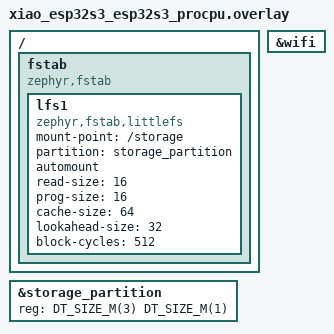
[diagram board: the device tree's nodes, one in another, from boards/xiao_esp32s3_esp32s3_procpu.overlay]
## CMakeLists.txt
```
# Copyright (c) 2022-2023 Golioth, Inc.
# SPDX-License-Identifier: Apache-2.0

cmake_minimum_required(VERSION 3.20.0)

# Conditionally add NCS/Zephyr-specific config
set(NCS_BOARD_LIST "nrf9160dk_nrf9160_ns")

if (BOARD IN_LIST NCS_BOARD_LIST)
    list(APPEND EXTRA_CONF_FILE prj-ncs.conf)
else()
    list(APPEND EXTRA_CONF_FILE prj-zephyr.conf)
endif(BOARD IN_LIST NCS_BOARD_LIST)

find_package(Zephyr REQUIRED HINTS $ENV{ZEPHYR_BASE})

project(example_template)

target_sources(app PRIVATE src/main.c)
target_sources_ifdef(CONFIG_BOOTLOADER_MCUBOOT app PRIVATE src/flash.c)
if(CONFIG_SOC_FAMILY_ESPRESSIF_ESP32 AND NOT CONFIG_BOOTLOADER_MCUBOOT)
    target_sources_ifndef(CONFIG_BOOTLOADER_MCUBOOT app PRIVATE src/mcuboot_assert.c)
endif()
```

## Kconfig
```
# Copyright (c) 2022-2023 Golioth, Inc.
# SPDX-License-Identifier: Apache-2.0

mainmenu "Golioth application options"

if DNS_RESOLVER

config DNS_SERVER_IP_ADDRESSES
	default y

config DNS_SERVER1
	default "1.1.1.1"

endif # DNS_RESOLVER

configdefault MCUBOOT_SHELL
	bool
    default y

# Workaround for not being able to have commas in macro arguments
DT_CHOSEN_ZEPHYR_DISPLAY := zephyr,display

configdefault LVGL
	bool
    default y if $(dt_chosen_enabled,$(DT_CHOSEN_ZEPHYR_DISPLAY))

configdefault LV_MEM_CUSTOM
	bool
    default y

configdefault LV_USE_LOG
	bool
    default y

configdefault LV_USE_LABEL
	bool
    default y

configdefault LV_USE_BTN
	bool
    default y

configdefault LV_USE_ARC
	bool
    default y

configdefault LV_USE_IMG
	bool
    default y

configdefault LV_USE_MONKEY
	bool
    default y

configdefault LV_FONT_MONTSERRAT_14
	bool
    default y

configdefault LV_Z_SHELL
	bool
    default y

configdefault LV_Z_MEM_POOL_SIZE
	int
    default 16384

source "Kconfig.zephyr"
```

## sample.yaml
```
# Copyright (c) 2024 Golioth, Inc.
# SPDX-License-Identifier: Apache-2.0

sample:
  description: Golioth Example Download Photo
  name: example_download_photo
common:
  harness: net
  platform_allow: >
    nrf9160dk_nrf9160_ns
  tags: golioth
```

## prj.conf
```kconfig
# Copyright (c) 2024 Golioth, Inc.
# SPDX-License-Identifier: Apache-2.0

# Enable Golioth Firmware SDK
CONFIG_GOLIOTH_FIRMWARE_SDK=y

# Golioth services used in this app
CONFIG_GOLIOTH_FW_UPDATE=y
CONFIG_GOLIOTH_SETTINGS=y
CONFIG_LOG_BACKEND_GOLIOTH=y

# Enable common sample library
CONFIG_GOLIOTH_SAMPLE_COMMON=y

# Configure Golioth SDK dependencies
CONFIG_ZVFS_EVENTFD_MAX=14
CONFIG_LOG_PROCESS_THREAD_STACK_SIZE=1536
CONFIG_MBEDTLS_ENABLE_HEAP=y
CONFIG_MBEDTLS_HEAP_SIZE=10240

CONFIG_NETWORKING=y
CONFIG_NET_IPV4=y
CONFIG_ZVFS_OPEN_MAX=23

# Application
CONFIG_MAIN_STACK_SIZE=8192
CONFIG_SYSTEM_WORKQUEUE_STACK_SIZE=2048
CONFIG_NET_LOG=y
CONFIG_NET_SHELL=y
CONFIG_REBOOT=y

# Flash memory (etc.) for firmware upgrade
CONFIG_FLASH=y
CONFIG_FLASH_MAP=y
CONFIG_STREAM_FLASH=y
CONFIG_IMG_MANAGER=y
CONFIG_IMG_ERASE_PROGRESSIVELY=y
CONFIG_REBOOT=y

# The rest of the runtime credentials config
CONFIG_SETTINGS=y
CONFIG_SETTINGS_RUNTIME=y
CONFIG_GOLIOTH_SAMPLE_SETTINGS=y
CONFIG_GOLIOTH_SAMPLE_SETTINGS_AUTOLOAD=y
CONFIG_GOLIOTH_SAMPLE_SETTINGS_SHELL=y

# Multiple OTA components to e.g. handle firmware upgrade and photo in single
# release
CONFIG_GOLIOTH_OTA_MAX_NUM_COMPONENTS=2

CONFIG_FILE_SYSTEM=y
CONFIG_FILE_SYSTEM_LITTLEFS=y

CONFIG_DISPLAY=y
CONFIG_DISPLAY_LOG_LEVEL_ERR=y

CONFIG_LOG=y
CONFIG_SHELL=y

CONFIG_COMMON_LIBC_MALLOC_ARENA_SIZE=65536
```

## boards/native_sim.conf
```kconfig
# Use offloaded sockets using host BSD sockets
CONFIG_ETH_DRIVER=n
CONFIG_ETH_NATIVE_POSIX=n
CONFIG_NET_DRIVERS=y
CONFIG_NET_SOCKETS=y
CONFIG_NET_SOCKETS_OFFLOAD=y
CONFIG_NET_NATIVE_OFFLOADED_SOCKETS=y
CONFIG_HEAP_MEM_POOL_SIZE=1024

# Use embedded libc to use Zephyr's eventfd instead of host eventfd
CONFIG_PICOLIBC=y

# Static networking
CONFIG_NET_CONFIG_LOG_LEVEL_DBG=y
CONFIG_NET_CONFIG_SETTINGS=y
CONFIG_NET_CONFIG_NEED_IPV4=y
CONFIG_NET_CONFIG_MY_IPV4_ADDR="192.0.2.1"
CONFIG_NET_CONFIG_MY_IPV4_GW="192.0.2.2"
CONFIG_NET_CONFIG_PEER_IPV4_ADDR="192.0.2.2"

# Disabled shell for using standard output
CONFIG_NET_SHELL=n
CONFIG_SHELL=n

# Make it the same as xiao_esp32s3 to use the same compiled images
CONFIG_LV_COLOR_16_SWAP=y
```

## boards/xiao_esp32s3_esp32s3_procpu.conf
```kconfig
CONFIG_WIFI=y
CONFIG_COMMON_LIBC_MALLOC_ARENA_SIZE=32768

CONFIG_NET_L2_ETHERNET=y

CONFIG_NET_DHCPV4=y

CONFIG_ESP32_WIFI_STA_AUTO_DHCPV4=y

CONFIG_NET_L2_WIFI_SHELL=y
CONFIG_GOLIOTH_SAMPLE_WIFI=y

# Runtime credentials for WiFi
CONFIG_GOLIOTH_SAMPLE_WIFI_SETTINGS=y

CONFIG_ESPTOOLPY_FLASHSIZE_8MB=y
```

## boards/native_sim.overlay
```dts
/ {
	fstab {
		compatible = "zephyr,fstab";
		lfs1: lfs1 {
			compatible = "zephyr,fstab,littlefs";
			mount-point = "/storage";
			partition = <&storage_partition>;
			automount;
			read-size = <16>;
			prog-size = <16>;
			cache-size = <64>;
			lookahead-size = <32>;
			block-cycles = <512>;
		};
	};
};

&storage_partition {
	reg = <DT_SIZE_M(1) DT_SIZE_M(1)>;
};
```

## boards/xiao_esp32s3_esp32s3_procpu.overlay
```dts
/ {
	fstab {
		compatible = "zephyr,fstab";
		lfs1: lfs1 {
			compatible = "zephyr,fstab,littlefs";
			mount-point = "/storage";
			partition = <&storage_partition>;
			automount;
			read-size = <16>;
			prog-size = <16>;
			cache-size = <64>;
			lookahead-size = <32>;
			block-cycles = <512>;
		};
	};
};

&storage_partition {
	reg = <DT_SIZE_M(3) DT_SIZE_M(1)>;
};

&wifi {
	status = "okay";
};
```

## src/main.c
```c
/*
 * Copyright (c) 2022-2023 Golioth, Inc.
 *
 * SPDX-License-Identifier: Apache-2.0
 */

#include <zephyr/logging/log.h>
LOG_MODULE_REGISTER(example_download_photo, LOG_LEVEL_DBG);

#include <app_version.h>
#include <golioth/client.h>
#include <golioth/ota.h>
#include <golioth/settings.h>
#include <samples/common/net_connect.h>
#include <samples/common/sample_credentials.h>
#include <zephyr/kernel.h>
#include <zephyr/fs/fs.h>

#include <zephyr/drivers/display.h>
#include <lvgl.h>

#include <mbedtls/sha256.h>

/* Current firmware version; update in VERSION file */
static const char *_current_version =
    STRINGIFY(APP_VERSION_MAJOR) "." STRINGIFY(APP_VERSION_MINOR) "." STRINGIFY(APP_PATCHLEVEL);

static struct golioth_client *client;
K_SEM_DEFINE(connected, 0, 1);

static k_tid_t _system_thread = 0;

static int32_t _loop_delay_s = 10;
#define LOOP_DELAY_S_MAX 43200
#define LOOP_DELAY_S_MIN 0


static void wake_system_thread(void)
{
    k_wakeup(_system_thread);
}

static void on_client_event(struct golioth_client *client,
                            enum golioth_client_event event,
                            void *arg)
{
    bool is_connected = (event == GOLIOTH_CLIENT_EVENT_CONNECTED);

    if (is_connected)
    {
        k_sem_give(&connected);
    }
    LOG_INF("Golioth client %s", is_connected ? "connected" : "disconnected");
}

static enum golioth_settings_status on_loop_delay_setting(int32_t new_value, void *arg)
{
    _loop_delay_s = new_value;
    LOG_INF("Set loop delay to %i seconds", new_value);
    wake_system_thread();
    return GOLIOTH_SETTINGS_SUCCESS;
}

static int app_settings_register(struct golioth_client *client)
{
    struct golioth_settings *settings = golioth_settings_init(client);

    int err = golioth_settings_register_int_with_range(settings,
                                                       "LOOP_DELAY_S",
                                                       LOOP_DELAY_S_MIN,
                                                       LOOP_DELAY_S_MAX,
                                                       on_loop_delay_setting,
                                                       NULL);

    if (err)
    {
        LOG_ERR("Failed to register settings callback: %d", err);
    }

    return err;
}

struct ota_observe_data
{
    struct golioth_ota_manifest manifest;
    struct k_sem manifest_received;
};

static void on_ota_manifest(struct golioth_client *client,
                            const struct golioth_response *response,
                            const char *path,
                            const uint8_t *payload,
                            size_t payload_size,
                            void *arg)
{
    struct ota_observe_data *data = arg;

    LOG_INF("Manifest received");

    if (response->status != GOLIOTH_OK)
    {
        return;
    }

    LOG_HEXDUMP_INF(payload, payload_size, "Received OTA manifest");

    enum golioth_ota_state state = golioth_ota_get_state();
    if (state == GOLIOTH_OTA_STATE_DOWNLOADING)
    {
        GLTH_LOGW(TAG, "Ignoring manifest while download in progress");
        return;
    }

    enum golioth_status status =
        golioth_ota_payload_as_manifest(payload, payload_size, &data->manifest);
    if (status != GOLIOTH_OK)
    {
        GLTH_LOGE(TAG, "Failed to parse manifest: %s", golioth_status_to_str(status));
        return;
    }

    if (data->manifest.num_components > 0) {
        k_sem_give(&data->manifest_received);
    }
}

enum golioth_status write_block(const struct golioth_ota_component *component,
                                uint32_t block_idx,
                                uint8_t *block_buffer,
                                size_t block_size,
                                bool is_last,
                                void *arg)
{
    const char *filename = component->package;
    struct fs_file_t fp = {};
    fs_mode_t flags = FS_O_CREATE | FS_O_WRITE;
    char path[32];
    int err;
    ssize_t ret;

    if (block_idx == 0) {
        flags |= FS_O_TRUNC;
    }

    sprintf(path, "/storage/%s", filename);

    err = fs_open(&fp, path, flags);
    if (err) {
        LOG_ERR("Failed to open %s: %d", filename, err);

        return err;
    }

    err = fs_seek(&fp, block_idx * CONFIG_GOLIOTH_BLOCKWISE_DOWNLOAD_BUFFER_SIZE, FS_SEEK_SET);
    if (err) {
        goto fp_close;
    }

    ret = fs_write(&fp, block_buffer, block_size);
    if (ret < 0) {
        goto fp_close;
    }

fp_close:
    fs_close(&fp);

    return GOLIOTH_OK;
}

static int greeting_show(void)
{
    mbedtls_sha256_context ctx;
    char hash[32];
    struct fs_file_t greeting_fp = {};
    int err;
    ssize_t ret;

    mbedtls_sha256_init(&ctx);

    err = mbedtls_sha256_starts(&ctx, 0);
    if (err) {
        return -EFAULT;
    }

    err = fs_open(&greeting_fp, "/storage/greeting", FS_O_READ);
    if (err) {
        LOG_ERR("Failed to open greeting: %d", err);

        return err;
    }

    while (true) {
        uint8_t buffer[16];

        ret = fs_read(&greeting_fp, buffer, sizeof(buffer));
        if (ret < 0) {
            err = ret;
            LOG_ERR("Failed to read: %d", err);
            goto greeting_close;
        }
        if (ret == 0) {
            break;
        }

        LOG_HEXDUMP_INF(buffer, ret, "greeting");

        err = mbedtls_sha256_update(&ctx, buffer, ret);
        if (err) {
            LOG_ERR("Failed to get update sha256: %d", err);
            goto greeting_close;
        }
    }

    err = mbedtls_sha256_finish(&ctx, hash);
    if (err) {
        LOG_ERR("Failed to finish sha256 hash: %d", err);
        return -EFAULT;
    }

    LOG_HEXDUMP_INF(hash, sizeof(hash), "hash");

greeting_close:
    fs_close(&greeting_fp);

    if (err) {
        return GOLIOTH_ERR_FAIL;
    }

    return 0;
}

static lv_img_dsc_t img_background;

static int background_show(void)
{
    char hash[32] = {};
    struct fs_dirent dirent;
    struct fs_file_t background_fp = {};
    lv_img_header_t *img_header;
    uint8_t *buffer;
    int err;
    ssize_t ret;

    err = fs_stat("/storage/background", &dirent);
    if (err) {
        if (err == -ENOENT) {
            LOG_WRN("No background image found on FS");
        } else {
            LOG_ERR("Failed to check/stat background image: %d", err);
        }

        return err;
    }

    LOG_INF("Background image file size: %zu", dirent.size);

    buffer = malloc(dirent.size);
    if (!buffer) {
        LOG_ERR("Failed to allocate memory");
        return -ENOMEM;
    }

    err = fs_open(&background_fp, "/storage/background", FS_O_READ);
    if (err) {
        LOG_WRN("Failed to load background: %d", err);
        goto buffer_free;
    }

    ret = fs_read(&background_fp, buffer, dirent.size);
    if (ret < 0) {
        LOG_ERR("Failed to read: %zd", ret);
        err = ret;
        goto background_close;
    }

    if (ret != dirent.size) {
        LOG_ERR("ret (%d) != dirent.size (%d)", (int) ret, (int) dirent.size);
        err = -EIO;
        goto background_close;
    }

    err = mbedtls_sha256(buffer, dirent.size, hash, 0);
    if (err) {
        LOG_ERR("Failed to get update sha256: %d", err);
        goto background_close;
    }

    LOG_HEXDUMP_INF(hash, sizeof(hash), "hash");

    img_header = (void *)buffer;
    img_background.header = *img_header;
    img_background.data_size = dirent.size - sizeof(*img_header);
    img_background.data = &buffer[sizeof(*img_header)];

    lv_obj_t * background = lv_img_create(lv_scr_act());
    lv_img_set_src(background, &img_background);
    lv_obj_align(background, LV_ALIGN_CENTER, 0, 0);

background_close:
    fs_close(&background_fp);

buffer_free:
    free(buffer);

    return err;
}

int main(void)
{
    enum golioth_status status;
    struct ota_observe_data ota_observe_data = {};
    int err;

    LOG_DBG("Start Golioth example_download_photo");
    LOG_INF("Firmware version: %s", _current_version);

    greeting_show();
    background_show();

    char count_str[11] = {0};
    const struct device *display_dev;
    lv_obj_t *count_label;
    uint32_t count = 0;

    display_dev = DEVICE_DT_GET(DT_CHOSEN(zephyr_display));
    if (!device_is_ready(display_dev)) {
        LOG_ERR("Device not ready, aborting test");
        return 0;
    }

    count_label = lv_label_create(lv_scr_act());
    lv_obj_align(count_label, LV_ALIGN_BOTTOM_MID, 0, 0);
    lv_label_set_text(count_label, "0");

    lv_task_handler();
    display_blanking_off(display_dev);

    /* Get system thread id so loop delay change event can wake main */
    _system_thread = k_current_get();

    /* Start the network connection */
    net_connect();

    /* Get the client configuration from auto-loaded settings */
    const struct golioth_client_config *client_config = golioth_sample_credentials_get();

    /* Create and start a Golioth Client */
    client = golioth_client_create(client_config);

    /* Register Golioth event callback */
    golioth_client_register_event_callback(client, on_client_event, &ota_observe_data);

    /* Register Golioth Settings service */
    app_settings_register(client);

    /* Block until connected to Golioth */
    k_sem_take(&connected, K_FOREVER);

    status = golioth_ota_report_state_sync(client,
                                           GOLIOTH_OTA_STATE_IDLE,
                                           GOLIOTH_OTA_REASON_READY,
                                           "main",
                                           _current_version,
                                           NULL,
                                           GOLIOTH_SYS_WAIT_FOREVER);

    if (status != GOLIOTH_OK)
    {
        GLTH_LOGE(TAG, "Failed to report firmware state: %d", status);
    }

    status = GOLIOTH_ERR_NULL;
    uint32_t retry_delay_s = 5;

    k_sem_init(&ota_observe_data.manifest_received, 0, 1);

    LOG_INF("Registering manifest observation");

    while (status != GOLIOTH_OK)
    {
        status = golioth_ota_observe_manifest_async(client, on_ota_manifest, &ota_observe_data);
        if (status == GOLIOTH_OK)
        {
            break;
        }

        GLTH_LOGW(TAG,
                  "Failed to observe manifest, retry in %" PRIu32 "s: %d",
                  retry_delay_s,
                  status);

        golioth_sys_msleep(retry_delay_s * 1000);

        retry_delay_s = retry_delay_s * 2;

        if (retry_delay_s > CONFIG_GOLIOTH_OTA_OBSERVATION_RETRY_MAX_DELAY_S)
        {
            retry_delay_s = CONFIG_GOLIOTH_OTA_OBSERVATION_RETRY_MAX_DELAY_S;
        }
    }

    LOG_INF("Waiting for FW update");

    while (true)
    {
        uint32_t count_cur = k_uptime_get() / 1000;
        if (count_cur != count) {
            count = count_cur;
            sprintf(count_str, "%d", (int) count);
            lv_label_set_text(count_label, count_str);
        }

        lv_task_handler();

        err = k_sem_take(&ota_observe_data.manifest_received, K_MSEC(10));
        if (!err) {
            LOG_INF("Received new manifest (num_components=%zu)", ota_observe_data.manifest.num_components);

            for (size_t i = 0; i < ota_observe_data.manifest.num_components; i++) {
                struct golioth_ota_component *component = &ota_observe_data.manifest.components[i];

                LOG_INF("component %zu: package=%s version=%s uri=%s hash=%s", i, component->package, component->version, component->uri, component->hash);

                status = golioth_ota_download_component(client, component, write_block, NULL);
            }
        }
    }
}
```

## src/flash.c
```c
/*
 * Copyright (c) 2021-2024 Golioth, Inc.
 *
 * SPDX-License-Identifier: Apache-2.0
 */

#include <zephyr/logging/log.h>
LOG_MODULE_DECLARE(example_download_photo);

#include <stdio.h>
#include <zephyr/storage/flash_map.h>

#include "flash.h"

#ifdef CONFIG_TRUSTED_EXECUTION_NONSECURE
#define SLOT0_LABEL slot0_ns_partition
#else
#define SLOT0_LABEL slot0_partition
#endif /* CONFIG_TRUSTED_EXECUTION_NONSECURE */

/* FIXED_PARTITION_ID() values used below are auto-generated by DT */
#define FLASH_AREA_IMAGE_PRIMARY FIXED_PARTITION_ID(SLOT0_LABEL)

/*
 * @note This is a copy of ERASED_VAL_32() from mcumgr.
 */
#define ERASED_VAL_32(x) (((x) << 24) | ((x) << 16) | ((x) << 8) | (x))

/**
 * Determines if the specified area of flash is completely unwritten.
 *
 * @note This is a copy of zephyr_img_mgmt_flash_check_empty() from mcumgr.
 */
static int flash_area_check_empty(const struct flash_area *fa,
                                  bool *out_empty)
{
    uint32_t data[16];
    off_t addr;
    off_t end;
    int bytes_to_read;
    int rc;
    int i;
    uint8_t erased_val;
    uint32_t erased_val_32;

    __ASSERT_NO_MSG(fa->fa_size % 4 == 0);

    erased_val = flash_area_erased_val(fa);
    erased_val_32 = ERASED_VAL_32(erased_val);

    end = fa->fa_size;
    for (addr = 0; addr < end; addr += sizeof(data)) {
        if (end - addr < sizeof(data)) {
            bytes_to_read = end - addr;
        } else {
            bytes_to_read = sizeof(data);
        }

        rc = flash_area_read(fa, addr, data, bytes_to_read);
        if (rc != 0) {
            flash_area_close(fa);
            return rc;
        }

        for (i = 0; i < bytes_to_read / 4; i++) {
            if (data[i] != erased_val_32) {
                *out_empty = false;
                flash_area_close(fa);
                return 0;
            }
        }
    }

    *out_empty = true;

    return 0;
}

static int flash_img_erase_if_needed(struct flash_img_context *ctx)
{
    bool empty;
    int err;

    if (IS_ENABLED(CONFIG_IMG_ERASE_PROGRESSIVELY)) {
        return 0;
    }

    err = flash_area_check_empty(ctx->flash_area, &empty);
    if (err) {
        return err;
    }

    if (empty) {
        return 0;
    }

    err = flash_area_erase(ctx->flash_area, 0, ctx->flash_area->fa_size);
    if (err) {
        return err;
    }

    return 0;
}

static const char *swap_type_str(int swap_type)
{
    switch (swap_type) {
    case BOOT_SWAP_TYPE_NONE:
        return "none";
    case BOOT_SWAP_TYPE_TEST:
        return "test";
    case BOOT_SWAP_TYPE_PERM:
        return "perm";
    case BOOT_SWAP_TYPE_REVERT:
        return "revert";
    case BOOT_SWAP_TYPE_FAIL:
        return "fail";
    }

    return "unknown";
}

int flash_img_prepare(struct flash_img_context *ctx)
{
    int swap_type;
    int err;

    swap_type = mcuboot_swap_type();
    switch (swap_type) {
    case BOOT_SWAP_TYPE_REVERT:
        LOG_WRN("'revert' swap type detected, it is not safe to continue");
        return -EBUSY;
    default:
        LOG_INF("swap type: %s", swap_type_str(swap_type));
        break;
    }

    err = flash_img_init(ctx);
    if (err) {
        LOG_ERR("failed to init: %d", err);
        return err;
    }

    err = flash_img_erase_if_needed(ctx);
    if (err) {
        LOG_ERR("failed to erase: %d", err);
        return err;
    }

    return 0;
}
```

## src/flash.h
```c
/*
 * Copyright (c) 2021-2024 Golioth, Inc.
 *
 * SPDX-License-Identifier: Apache-2.0
 */

#ifndef __APP_FLASH_H__
#define __APP_FLASH_H__

#ifdef CONFIG_BOOTLOADER_MCUBOOT

#include <zephyr/dfu/flash_img.h>
#include <zephyr/dfu/mcuboot.h>
#include <zephyr/types.h>

int flash_img_prepare(struct flash_img_context *flash);

#else /* CONFIG_BOOTLOADER_MCUBOOT */

#include <stdbool.h>
#include <stddef.h>
#include <stdint.h>

struct flash_img_context {
	/* empty */
};

static inline int flash_img_prepare(struct flash_img_context *flash)
{
	return 0;
}

static inline
int flash_img_buffered_write(struct flash_img_context *ctx, const uint8_t *data,
			     size_t len, bool flush)
{
	return 0;
}

/** Boot upgrade request modes */
#define BOOT_UPGRADE_TEST       0
#define BOOT_UPGRADE_PERMANENT  1

static inline int boot_request_upgrade(int permanent)
{
	return 0;
}

static inline bool boot_is_img_confirmed(void)
{
	return true;
}

static inline int boot_write_img_confirmed(void)
{
	return 0;
}

#endif /* CONFIG_BOOTLOADER_MCUBOOT */

#endif /* __APP_FLASH_H__ */
```

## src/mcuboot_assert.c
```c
/*
 * Copyright (c) 2024 Golioth, Inc.
 *
 * SPDX-License-Identifier: Apache-2.0
 */

#include <zephyr/sys/__assert.h>

/* Workaround for Espressif HAL, which expects SOME mcuboot_assert_handler() implementation. */
void mcuboot_assert_handler(const char *file, int line, const char *func)
{
    __ASSERT_NO_MSG(false);
}
```
